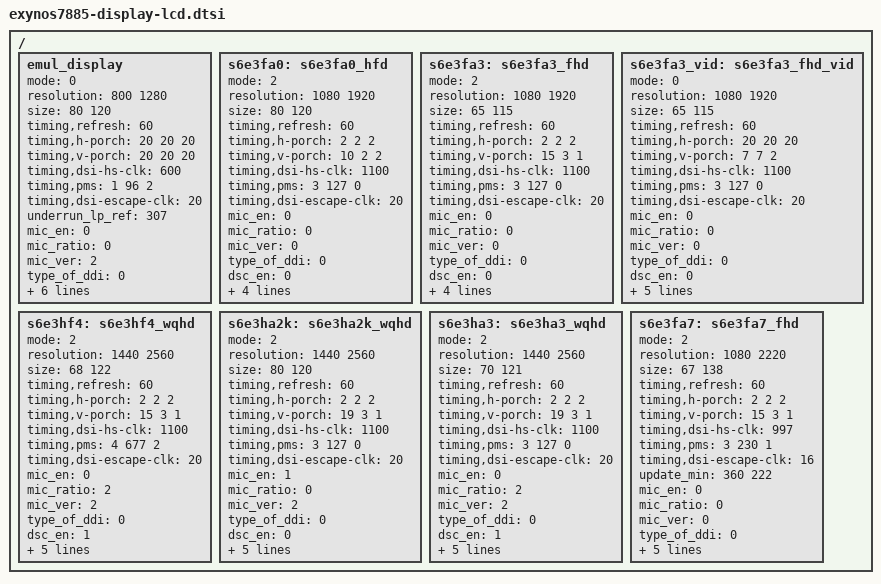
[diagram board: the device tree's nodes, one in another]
/*
 * SAMSUNG LCD Panel Device Tree Source
 *
 * Copyright (c) 2016 Samsung Electronics Co., Ltd.
 *		http://www.samsung.com
 *
 * This program is free software; you can redistribute it and/or modify
 * it under the terms of the GNU General Public License version 2 as
 * published by the Free Software Foundation.
*/

/ {
	fragment@lcd {
		target-path = "/";
		__overlay__ {
			emul_display: emul_display {
				mode = <0>; /* 0: video mode, 1: DP command mode, 2: MIPI command mode */
				resolution = <800 1280>;
				size = <80 120>;
				timing,refresh = <60>;
				timing,h-porch = <20 20 20>;
				timing,v-porch = <20 20 20>;
				timing,dsi-hs-clk = <600>;
				/* TODO : pms value to be set */
				timing,pms = <1 96 2>;
				timing,dsi-escape-clk = <20>;
				underrun_lp_ref = <307>;
				mic_en = <0>;		/* 0: Disable, 1: Enable */
				mic_ratio = <0>;	/* 0: 1/2 mic, 1: 1/3 mic */
				mic_ver = <2>;		/* 0: mic v1.1, 1: v1.2, 2: v2.0 */
				type_of_ddi = <0>;	/* 0: Samsung Mobile, 1: MAGNA, 2: Normal(Etc) */
				dsc_en = <0>;		/* 0: Disable, 1: Enable */
				dsc_cnt = <0>;		/* used DSC count */
				dsc_slice_num = <0>;	/* count of dsc slice */
				data_lane = <4>;	/* number of using data lane */
				cmd_underrun_lp_ref = <1203>;	/* for underrun detect at command mode*/
				vt_compensation = <2871>;	/* for underrun detect at video mode*/
			};

			s6e3fa0: s6e3fa0_hfd {
				mode = <2>; /* 0: video mode, 1: DP command mode, 2: MIPI command mode */
				resolution = <1080 1920>;
				size = <80 120>;
				timing,refresh = <60>;
				timing,h-porch = <2 2 2>;
				timing,v-porch = <10 2 2>;
				timing,dsi-hs-clk = <1100>;
				/* TODO : pms value to be set */
				timing,pms = <3 127 0>;
				timing,dsi-escape-clk = <20>;
				mic_en = <0>;		/* 0: Disable, 1: Enable */
				mic_ratio = <0>;	/* 0: 1/2 mic, 1: 1/3 mic */
				mic_ver = <0>;		/* 0: mic v1.1, 1: v1.2, 2: v2.0 */
				type_of_ddi = <0>;	/* 0: Samsung Mobile, 1: MAGNA, 2: Normal(Etc) */
				dsc_en = <0>;		/* 0: Disable, 1: Enable */
				dsc_cnt = <0>;		/* used DSC count */
				dsc_slice_num = <0>;	/* count of dsc slice */
				data_lane = <4>;	/* number of using data lane */
				cmd_underrun_lp_ref = <4942>;	/* for underrun detect at command mode*/
			};

			s6e3fa3: s6e3fa3_fhd {
				mode = <2>; /* 0: video mode, 1: DP command mode, 2: MIPI command mode */
				resolution = <1080 1920>;
				size = <65 115>;
				timing,refresh = <60>;
				timing,h-porch = <2 2 2>;
				timing,v-porch = <15 3 1>;
				timing,dsi-hs-clk = <1100>;
				/* TODO : pms value to be set */
				timing,pms = <3 127 0>;
				timing,dsi-escape-clk = <20>;
				mic_en = <0>;		/* 0: Disable, 1: Enable */
				mic_ratio = <0>;	/* 0: 1/2 mic, 1: 1/3 mic */
				mic_ver = <0>;		/* 0: mic v1.1, 1: v1.2, 2: v2.0 */
				type_of_ddi = <0>;	/* 0: Samsung Mobile, 1: MAGNA, 2: Normal(Etc) */
				dsc_en = <0>;		/* 0: Disable, 1: Enable */
				dsc_cnt = <0>;		/* used DSC count */
				dsc_slice_num = <0>;	/* count of dsc slice */
				data_lane = <4>;	/* number of using data lane */
				cmd_underrun_lp_ref = <4942>;	/* for underrun detect at command mode*/
			};

			s6e3fa3_vid: s6e3fa3_fhd_vid {
				mode = <0>; /* 0: video mode, 1: DP command mode, 2: MIPI command mode */
				resolution = <1080 1920>;
				size = <65 115>;
				timing,refresh = <60>;
				timing,h-porch = <20 20 20>;
				timing,v-porch = <7 7 2>;
				timing,dsi-hs-clk = <1100>;
				/* TODO : pms value to be set */
				timing,pms = <3 127 0>;
				timing,dsi-escape-clk = <20>;
				mic_en = <0>;		/* 0: Disable, 1: Enable */
				mic_ratio = <0>;	/* 0: 1/2 mic, 1: 1/3 mic */
				mic_ver = <0>;		/* 0: mic v1.1, 1: v1.2, 2: v2.0 */
				type_of_ddi = <0>;	/* 0: Samsung Mobile, 1: MAGNA, 2: Normal(Etc) */
				dsc_en = <0>;		/* 0: Disable, 1: Enable */
				dsc_cnt = <0>;		/* used DSC count */
				dsc_slice_num = <0>;	/* count of dsc slice */
				data_lane = <4>;	/* number of using data lane */
				cmd_underrun_lp_ref = <4942>;	/* for underrun detect at command mode*/
				vt_compensation = <1284>;	/* for underrun detect at video mode*/
			};

			s6e3hf4: s6e3hf4_wqhd {
				mode = <2>;		/* 0: video mode, 1: DP command mode, 2: MIPI command mode */
				resolution = <1440 2560>;
				size = <68 122>;
				timing,refresh = <60>;
				timing,h-porch = <2 2 2>;
				timing,v-porch = <15 3 1>;
				timing,dsi-hs-clk = <1100>;
				timing,pms = <4 677 2>;
				timing,dsi-escape-clk = <20>;
				mic_en = <0>;		/* 0: Disable, 1: Enable */
				mic_ratio = <2>;	/* 0: 1/2 mic, 1: 1/3 mic */
				mic_ver = <2>;		/* 0: mic v1.1, 1: v1.2, 2: v2.0 */
				type_of_ddi = <0>;	/* 0: Samsung Mobile, 1: MAGNA, 2: Normal(Etc) */
				dsc_en = <1>;		/* 0: Disable, 1: Enable */
				dsc_cnt = <2>;		/* used DSC count */
				dsc_slice_num = <4>;	/* count of dsc slice */
				dsc_slice_h = <64>;	/* height of dsc slice */
				data_lane = <4>;	/* number of using data lane */
				cmd_underrun_lp_ref = <5629>;	/* for underrun detect*/
			};

			s6e3ha2k: s6e3ha2k_wqhd {
				mode = <2>;		/* 0: video mode, 1: DP command mode, 2: MIPI command mode */
				resolution = <1440 2560>;
				size = <80 120>;
				timing,refresh = <60>;
				timing,h-porch = <2 2 2>;
				timing,v-porch = <19 3 1>;
				timing,dsi-hs-clk = <1100>;
				timing,pms = <3 127 0>;
				timing,dsi-escape-clk = <20>;
				mic_en = <1>;		/* 0: Disable, 1: Enable */
				mic_ratio = <0>;	/* 0: 1/2 mic, 1: 1/3 mic */
				mic_ver = <2>;		/* 0: mic v1.1, 1: v1.2, 2: v2.0 */
				type_of_ddi = <0>;	/* 0: Samsung Mobile, 1: MAGNA, 2: Normal(Etc) */
				dsc_en = <0>;		/* 0: Disable, 1: Enable */
				dsc_cnt = <0>;		/* used DSC count */
				dsc_slice_num = <0>;	/* count of dsc slice */
				dsc_slice_h = <0>;	/* height of dsc slice */
				data_lane = <4>;	/* number of using data lane */
				cmd_underrun_lp_ref = <1203>;	/* for underrun detect*/
			};

			s6e3ha3: s6e3ha3_wqhd {
				mode = <2>;		/* 0: video mode, 1: DP command mode, 2: MIPI command mode */
				resolution = <1440 2560>;
				size = <70 121>;
				timing,refresh = <60>;
				timing,h-porch = <2 2 2>;
				timing,v-porch = <19 3 1>;
				timing,dsi-hs-clk = <1100>;
				timing,pms = <3 127 0>;
				timing,dsi-escape-clk = <20>;
				mic_en = <0>;		/* 0: Disable, 1: Enable */
				mic_ratio = <2>;	/* 0: 1/2 mic, 1: 1/3 mic */
				mic_ver = <2>;		/* 0: mic v1.1, 1: v1.2, 2: v2.0 */
				type_of_ddi = <0>;	/* 0: Samsung Mobile, 1: MAGNA, 2: Normal(Etc) */
				dsc_en = <1>;		/* 0: Disable, 1: Enable */
				dsc_cnt = <1>;		/* used DSC count */
				dsc_slice_num = <1>;	/* count of dsc slice */
				dsc_slice_h = <32>;	/* height of dsc slice */
				data_lane = <4>;	/* number of using data lane */
				cmd_underrun_lp_ref = <1203>;	/* for underrun detect*/
			};

			s6e3fa7: s6e3fa7_fhd {
				mode = <2>; /* 0: video mode, 1: DP command mode, 2: MIPI command mode */
				resolution = <1080 2220>;
				size = <67 138>;	/* 67.176 x 138.084 */
				timing,refresh = <60>;
				timing,h-porch = <2 2 2>;
				timing,v-porch = <15 3 1>;
				timing,dsi-hs-clk = <997>;
				timing,pms = <3 230 1>;
				timing,dsi-escape-clk = <16>;
				update_min = <360 222>;
				mic_en = <0>;		/* 0: Disable, 1: Enable */
				mic_ratio = <0>;	/* 0: 1/2 mic, 1: 1/3 mic */
				mic_ver = <0>;		/* 0: mic v1.1, 1: v1.2, 2: v2.0 */
				type_of_ddi = <0>;	/* 0: Samsung Mobile, 1: MAGNA, 2: Normal(Etc) */
				dsc_en = <0>;		/* 0: Disable, 1: Enable */
				dsc_cnt = <0>;		/* used DSC count */
				dsc_slice_num = <0>;	/* count of dsc slice */
				data_lane = <4>;	/* number of using data lane */
				cmd_underrun_lp_ref = <2498>;	/* for underrun detect at command mode */
			};
		};
	};
};
